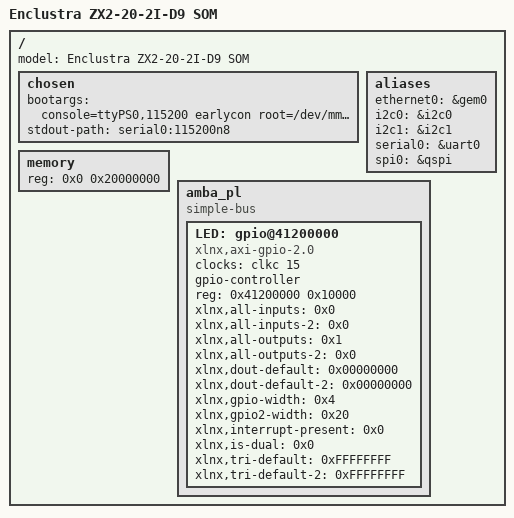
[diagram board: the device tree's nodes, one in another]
// SPDX-License-Identifier: GPL-2.0+
/*
 *  Copyright (C) 2020 Enclustra GmbH
 *
 * This software is licensed under the terms of the GNU General Public
 * License version 2, as published by the Free Software Foundation, and
 * may be copied, distributed, and modified under those terms.
 *
 * This program is distributed in the hope that it will be useful,
 * but WITHOUT ANY WARRANTY; without even the implied warranty of
 * MERCHANTABILITY or FITNESS FOR A PARTICULAR PURPOSE.  See the
 * GNU General Public License for more details.
 */


#include "zynq-7000.dtsi"
#include "zynq_enclustra_common.dtsi"
#include "zynq_enclustra_mars_zx2.dtsi"

/ {
	model = "Enclustra ZX2-20-2I-D9 SOM";

	chosen {
		bootargs = "console=ttyPS0,115200 earlycon root=/dev/mmcblk0p2 rw rootfstype=ext4 rootwait";
		stdout-path = "serial0:115200n8";
	};

	aliases {
		ethernet0 = &gem0;
		i2c0 = &i2c0;
		i2c1 = &i2c1;
		serial0 = &uart0;
		spi0 = &qspi;
	};

	memory {
		device_type = "memory";
		reg = <0x0 0x20000000>;
	};

/******************** PL entries **********************/

	amba_pl: amba_pl {
		#address-cells = <1>;
		#size-cells = <1>;
		compatible = "simple-bus";
		ranges ;
		LED: gpio@41200000 {
			#gpio-cells = <3>;
			clock-names = "s_axi_aclk";
			clocks = <&clkc 15>;
			compatible = "xlnx,axi-gpio-2.0", "xlnx,xps-gpio-1.00.a";
			gpio-controller ;
			reg = <0x41200000 0x10000>;
			xlnx,all-inputs = <0x0>;
			xlnx,all-inputs-2 = <0x0>;
			xlnx,all-outputs = <0x1>;
			xlnx,all-outputs-2 = <0x0>;
			xlnx,dout-default = <0x00000000>;
			xlnx,dout-default-2 = <0x00000000>;
			xlnx,gpio-width = <0x4>;
			xlnx,gpio2-width = <0x20>;
			xlnx,interrupt-present = <0x0>;
			xlnx,is-dual = <0x0>;
			xlnx,tri-default = <0xFFFFFFFF>;
			xlnx,tri-default-2 = <0xFFFFFFFF>;
		};
	};

/******************** PL entries **********************/

};
